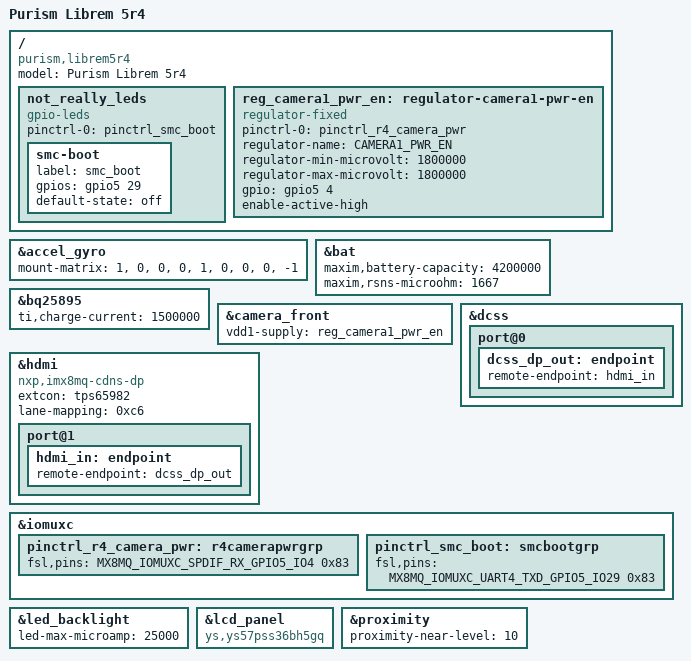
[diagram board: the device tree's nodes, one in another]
// SPDX-License-Identifier: (GPL-2.0+ OR MIT)
// Copyright (C) 2020 Purism SPC <kernel@puri.sm>

/dts-v1/;

#include "imx8mq-librem5.dtsi"

/ {
	model = "Purism Librem 5r4";
	compatible = "purism,librem5r4", "purism,librem5", "fsl,imx8mq";

	not_really_leds {
		compatible = "gpio-leds";
		pinctrl-names = "default";
		pinctrl-0 = <&pinctrl_smc_boot>;

		smc-boot {
			label = "smc_boot";
			gpios = <&gpio5 29 GPIO_ACTIVE_HIGH>;
			default-state = "off";
		};
	};

	reg_camera1_pwr_en: regulator-camera1-pwr-en {
		compatible = "regulator-fixed";
		pinctrl-names = "default";
		pinctrl-0 = <&pinctrl_r4_camera_pwr>;
		regulator-name = "CAMERA1_PWR_EN";
		regulator-min-microvolt = <1800000>;
		regulator-max-microvolt = <1800000>;
		gpio = <&gpio5 4 GPIO_ACTIVE_HIGH>;
		enable-active-high;
	};
};

&accel_gyro {
	mount-matrix =  "1",  "0",  "0",
			"0",  "1",  "0",
			"0",  "0", "-1";
};

&bat {
	maxim,battery-capacity = <4200000>; /* uAh */
	maxim,rsns-microohm = <1667>;
};

&bq25895 {
	ti,charge-current = <1500000>; /* uA */
};

&camera_front {
	vdd1-supply = <&reg_camera1_pwr_en>;
};

/delete-node/ &dcss_dsi_out;
/delete-node/ &mipi_dsi_dcss_in;
&dcss {
	status = "okay";

	port@0 {
		dcss_dp_out: endpoint {
			  remote-endpoint = <&hdmi_in>;
		};
	};
};

&hdmi {
	compatible = "nxp,imx8mq-cdns-dp";
	extcon = <&tps65982>;
	lane-mapping = <0xc6>;
	status = "okay";
	port@1 {
		hdmi_in: endpoint {
			remote-endpoint = <&dcss_dp_out>;
		};
	};
};

&iomuxc {
	pinctrl_r4_camera_pwr: r4camerapwrgrp {
		fsl,pins = <
			MX8MQ_IOMUXC_SPDIF_RX_GPIO5_IO4		0x83
		>;
	};

	pinctrl_smc_boot: smcbootgrp {
		 fsl,pins = <
			 /* SMC_BOOT0 */
			 MX8MQ_IOMUXC_UART4_TXD_GPIO5_IO29	0x83
		>;
	};
};

&led_backlight {
	led-max-microamp = <25000>;
};

&lcd_panel {
	compatible = "ys,ys57pss36bh5gq";
};

&proximity {
	proximity-near-level = <10>;
};
